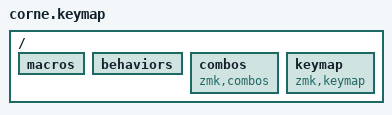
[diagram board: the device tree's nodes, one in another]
/*
 * Copyright (c) 2020 The ZMK Contributors
 *
 * SPDX-License-Identifier: MIT
 */

#include <behaviors.dtsi>
#include <dt-bindings/zmk/keys.h>
#include <dt-bindings/zmk/bt.h>

/* Global */
#include "os/all/times.dtsi"
#include "os/all/general.dtsi"
#include "os/windows/layers.dtsi"
#include "os/android/layers.dtsi"

/* Keys */
#include "os/all/keys.dtsi"
#include "os/windows/keys.dtsi"
#include "os/android/keys.dtsi"

/* Helpers */
#include "helpers/general.dtsi"
#include "helpers/macros.dtsi"
#include "helpers/hold.dtsi"
#include "helpers/morph.dtsi"

/ {
    macros {
        #include "os/all/macros/layers.dtsi"
        #include "os/all/macros/settings.dtsi"

        #include "os/windows/macros/layers.dtsi"
        #include "os/windows/macros/int.dtsi"
        #include "os/windows/macros/dev.dtsi"

        #include "os/android/macros/layers.dtsi"
        #include "os/android/macros/int.dtsi"
        #include "os/android/macros/dev.dtsi"
        #include "os/android/macros/stg.dtsi"
    };
};

/ {
    behaviors {
        #include "os/all/morph/shared.dtsi"
        #include "os/all/morph/num.dtsi"
        #include "os/all/hold/shared.dtsi"

        #include "os/windows/morph/layers.dtsi"
        #include "os/windows/morph/base.dtsi"
        #include "os/windows/morph/int.dtsi"
        #include "os/windows/morph/actions.dtsi"
        #include "os/windows/morph/dev.dtsi"
        #include "os/windows/hold/layers.dtsi"
        #include "os/windows/hold/base.dtsi"
        #include "os/windows/hold/dev.dtsi"

        #include "os/android/morph/layers.dtsi"
        #include "os/android/morph/base.dtsi"
        #include "os/android/morph/int.dtsi"
        #include "os/android/morph/dev.dtsi"
        #include "os/android/hold/layers.dtsi"
        #include "os/android/hold/base.dtsi"
        #include "os/android/hold/dev.dtsi"
    };
};

/ {
    combos {
        compatible = "zmk,combos";

        #include "os/windows/combos/base.dtsi"
        #include "os/windows/combos/help.dtsi"

        #include "os/android/combos/base.dtsi"
    };
};

/ {
    keymap {
        compatible = "zmk,keymap";

        #include "os/windows/keymap.dtsi"
        #include "os/android/keymap.dtsi"
    };
};
